# npcx4m8f register map
Registers are 8-bit, read-write, no defined reset value unless marked. A register's access mark holds for its fields unless they carry their own. Offsets are from the block's base; [hi:lo] are bit positions; {n}, {i} and the like mark numbered series.

## GPIO2 — GENERAL-PURPOSE I/O
Base 0x40085000
0x00 P2DOUT
0x01 P2DIN
0x02 P2DIR
0x03 P2PULL
0x04 P2PUD
0x05 P2ENVDD
0x06 P2OTYPE

## GPIO3 — GENERAL-PURPOSE I/O
Base 0x40087000
0x00 P3DOUT
0x01 P3DIN
0x02 P3DIR
0x03 P3PULL
0x04 P3PUD
0x05 P3ENVDD
0x06 P3OTYPE

## GPIO4 — GENERAL-PURPOSE I/O
Base 0x40089000
0x00 P4DOUT
0x01 P4DIN
0x02 P4DIR
0x03 P4PULL
0x04 P4PUD
0x05 P4ENVDD
0x06 P4OTYPE

## GPIO5 — GENERAL-PURPOSE I/O
Base 0x4008B000
0x00 P5DOUT
0x01 P5DIN
0x02 P5DIR
0x03 P5PULL
0x04 P5PUD
0x05 P5ENVDD
0x06 P5OTYPE

## GPIO6 — GENERAL-PURPOSE I/O
Base 0x4008D000
0x00 P6DOUT
0x01 P6DIN
0x02 P6DIR
0x03 P6PULL
0x04 P6PUD
0x05 P6ENVDD
0x06 P6OTYPE

## GPIO7 — GENERAL-PURPOSE I/O
Base 0x4008F000
0x00 P7DOUT
0x01 P7DIN
0x02 P7DIR
0x03 P7PULL
0x04 P7PUD
0x05 P7ENVDD
0x06 P7OTYPE

## GPIO8 — GENERAL-PURPOSE I/O
Base 0x40091000
0x00 P8DOUT
0x01 P8DIN
0x02 P8DIR
0x03 P8PULL
0x04 P8PUD
0x05 P8ENVDD
0x06 P8OTYPE

## GPIO9 — GENERAL-PURPOSE I/O
Base 0x40093000
0x00 P9DOUT
0x01 P9DIN
0x02 P9DIR
0x03 P9PULL
0x04 P9PUD
0x05 P9ENVDD
0x06 P9OTYPE

## GPIOA — GENERAL-PURPOSE I/O
Base 0x40095000
0x00 PADOUT
0x01 PADIN
0x02 PADIR
0x03 PAPULL
0x04 PAPUD
0x05 PAENVDD
0x06 PAOTYPE

## GPIOB — GENERAL-PURPOSE I/O
Base 0x40097000
Same registers: GPIOC 0x40099000, GPIOD 0x4009B000, GPIOE 0x4009D000
0x00 PBDOUT
0x01 PBDIN
0x02 PBDIR
0x03 PBPULL
0x04 PBPUD
0x05 PBENVDD
0x06 PBOTYPE

## SMB1 — SMBus-Interface 1
Base 0x40009000
Same registers: SMB2 0x4000B000, SMB3 0x400C0000, SMB4 0x400C2000
0x00 SMBnSDA
  [7:0] SMB_DAT
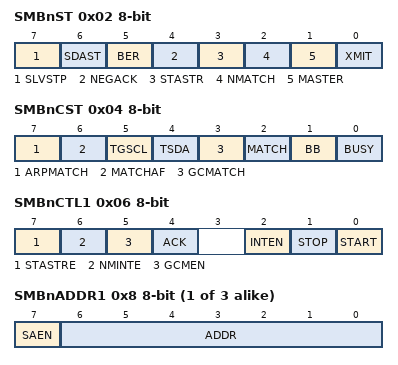
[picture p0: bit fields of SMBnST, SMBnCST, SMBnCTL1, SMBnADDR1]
0x02 SMBnST
  [7] SLVSTP, [6] SDAST, [5] BER, [4] NEGACK, [3] STASTR, [2] NMATCH, [1] MASTER, [0] XMIT
0x04 SMBnCST
  [7] ARPMATCH, [6] MATCHAF, [5] TGSCL, [4] TSDA, [3] GCMATCH, [2] MATCH, [1] BB, [0] BUSY
0x06 SMBnCTL1
  [7] STASTRE, [6] NMINTE, [5] GCMEN, [4] ACK, [2] INTEN, [1] STOP, [0] START
{0x4+4i} SMBnADDR{i} (i=1..3)
  [7] SAEN, [6:0] ADDR
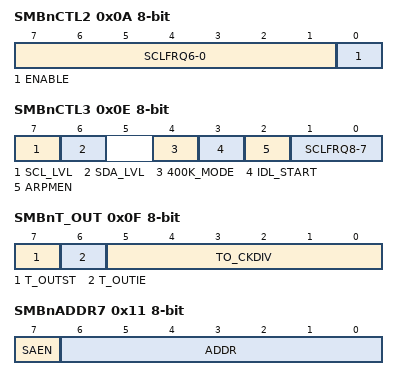
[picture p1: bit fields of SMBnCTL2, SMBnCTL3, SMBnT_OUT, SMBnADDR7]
0x0A SMBnCTL2
  [7:1] SCLFRQ6-0, [0] ENABLE
0x0E SMBnCTL3
  [7] SCL_LVL, [6] SDA_LVL, [4] 400K_MODE, [3] IDL_START, [2] ARPMEN, [1:0] SCLFRQ8-7
0x0F SMBnT_OUT
  [7] T_OUTST, [6] T_OUTIE, [5:0] TO_CKDIV
0x11 SMBnADDR7
  [7] SAEN, [6:0] ADDR
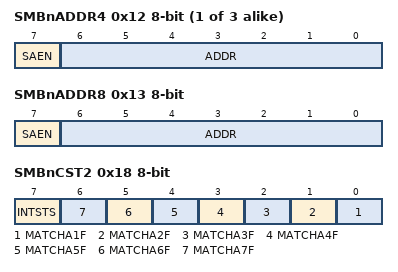
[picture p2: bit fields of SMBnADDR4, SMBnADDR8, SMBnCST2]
{0xA+2i} SMBnADDR{i} (i=4..6)
  [7] SAEN, [6:0] ADDR
0x13 SMBnADDR8
  [7] SAEN, [6:0] ADDR
0x18 SMBnCST2
  [7] INTSTS, [n-1] MATCHA{n}F (n=1..7)
0x19 SMBnCST3
  [0] MATCHA8F
0x1A SMBnCTL4
  [5:0] HLDT
0x1C SMBnSCLLT
  [7:0] SCLLT7-0
0x1E SMBnSCLHT
  [7:0] SCLHT7-0

## LCT — LONG COUNTDOWN TIMER
Base 0x400D7000
0x00 LCTVER
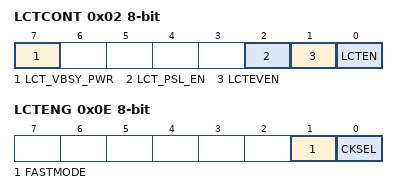
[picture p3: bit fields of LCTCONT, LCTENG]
0x02 LCTCONT
  [7] LCT_VBSY_PWR, [2] LCT_PSL_EN, [1] LCTEVEN, [0] LCTEN
0x04 LCTSTAT
  [0] LCTEVST
0x05 LCTSECOND
0x06 LCTMINUT
0x08 LCTHOUR
  [4:0] HOURS
0x0A LCTDAY
  [4:0] DAYS
0x0C LCTWEEK
  [3:0] WEEKS
0x0E LCTENG
  [1] FASTMODE, [0] CKSEL

## MTC — MONOTONIC COUNTER
Base 0x400B7000
0x00 TTC 32-bit
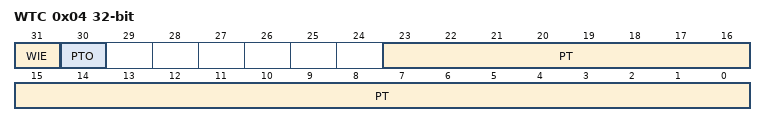
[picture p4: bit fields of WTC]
0x04 WTC 32-bit
  [31] WIE, [30] PTO, [23:0] PT
0x08 MTCTST
  [0] MTFEN

## TWD — TIMER AND WATCHDOG
Base 0x400D8000
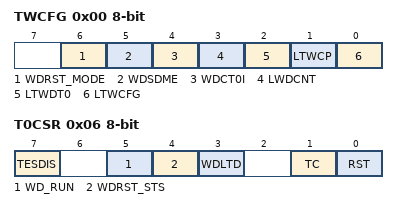
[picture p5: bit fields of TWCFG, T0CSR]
0x00 TWCFG
  [6] WDRST_MODE, [5] WDSDME, [4] WDCT0I, [3] LWDCNT, [2] LTWDT0, [1] LTWCP, [0] LTWCFG
0x02 TWCP
0x04 TWDT0 16-bit
0x06 T0CSR
  [7] TESDIS, [5] WD_RUN, [4] WDRST_STS, [3] WDLTD, [1] TC, [0] RST
0x08 WDCNT
0x0A WDSDM
0x0C TWMT0 16-bit
0x0E TWMWD
0x10 WDCP

## ITIM16-1 — INTERNAL 16-BIT TIMER
Base 0x400B0000
Same registers: ITIM16-2 0x400B2000, ITIM16-3 0x400B4000, ITIM16-4 0x400B6000, ITIM16-5 0x400B8000, ITIM16-6 0x400BA000
0x00 ITCNTn
0x01 ITPREn
0x02 ITCNT16n 16-bit
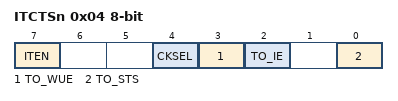
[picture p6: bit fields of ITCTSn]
0x04 ITCTSn
  [7] ITEN, [4] CKSEL, [3] TO_WUE, [2] TO_IE, [0] TO_STS

## MFT16-1 — MULTI-FUNCTION 16-BIT TIMER
Base 0x400E1000
Same registers: MFT16-2 0x400E3000, MFT16-3 0x400E5000
0x00 TnCNT1
0x02 TnCRA
0x04 TnCRB
0x06 TnCNT2
0x08 TnPRSC
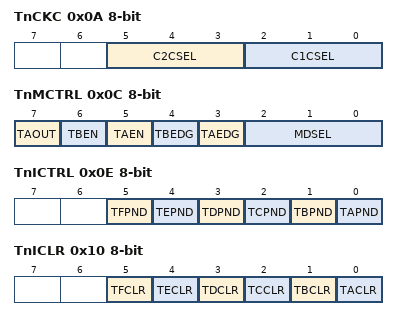
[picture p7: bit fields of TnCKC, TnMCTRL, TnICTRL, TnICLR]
0x0A TnCKC
  [5:3] C2CSEL, [2:0] C1CSEL
0x0C TnMCTRL
  [7] TAOUT, [6] TBEN, [5] TAEN, [4] TBEDG, [3] TAEDG, [2:0] MDSEL
0x0E TnICTRL
  [5] TFPND, [4] TEPND, [3] TDPND, [2] TCPND, [1] TBPND, [0] TAPND
0x10 TnICLR
  [5] TFCLR, [4] TECLR, [3] TDCLR, [2] TCCLR, [1] TBCLR, [0] TACLR
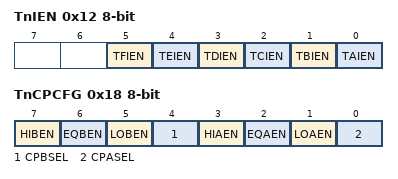
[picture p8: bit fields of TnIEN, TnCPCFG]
0x12 TnIEN
  [5] TFIEN, [4] TEIEN, [3] TDIEN, [2] TCIEN, [1] TBIEN, [0] TAIEN
0x14 TnCPA
0x16 TnCPB
0x18 TnCPCFG
  [7] HIBEN, [6] EQBEN, [5] LOBEN, [4] CPBSEL, [3] HIAEN, [2] EQAEN, [1] LOAEN, [0] CPASEL
